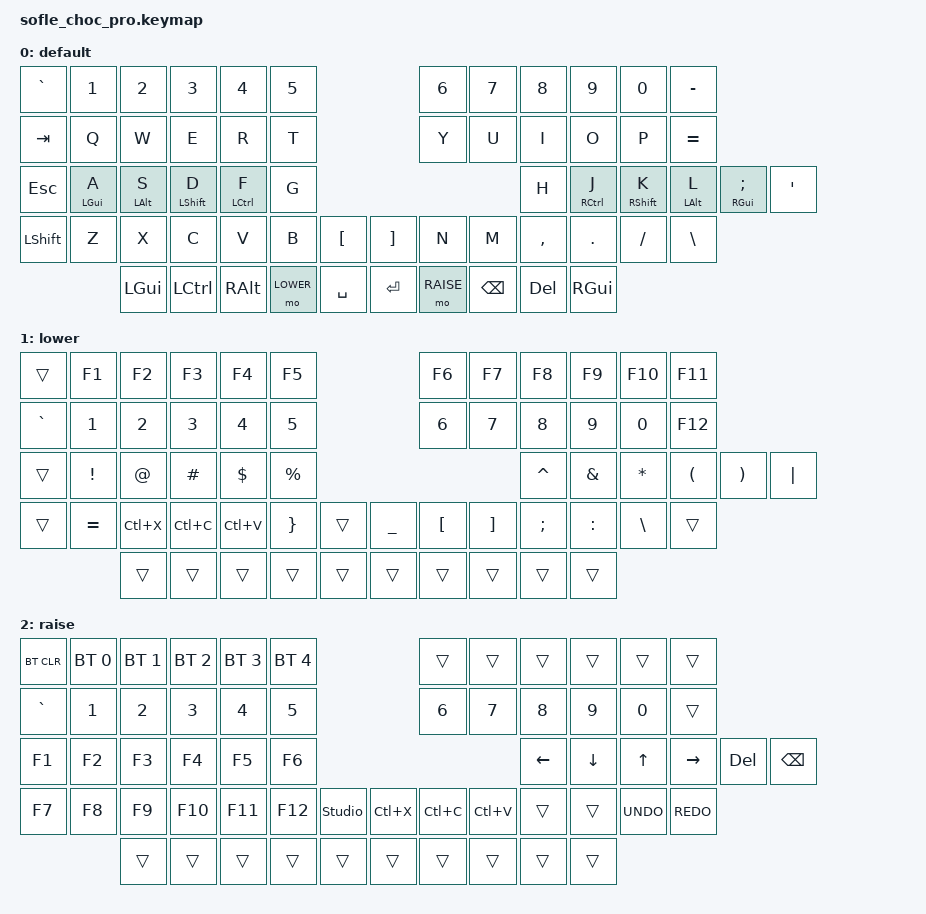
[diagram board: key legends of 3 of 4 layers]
/*
* Copyright (c) 2020 The ZMK Contributors
*
* SPDX-License-Identifier: MIT
*/

#include <behaviors.dtsi>
#include <dt-bindings/zmk/bt.h>
#include <dt-bindings/zmk/ext_power.h>
#include <dt-bindings/zmk/keys.h>
#include <dt-bindings/zmk/rgb.h>

#define BASE 0
#define LOWER 1
#define RAISE 2
#define ADJUST 3

/ {
    // Activate ADJUST layer by pressing raise and lower

    conditional_layers {
        compatible = "zmk,conditional-layers";

        adjust_layer {
            if-layers = <LOWER RAISE>;
            then-layer = <ADJUST>;
        };
    };

    behaviors {
        hml_pinky: hml_pinky {
            compatible = "zmk,behavior-hold-tap";
            label = "HML_PINKY";
            bindings = <&kp>, <&kp>;

            #binding-cells = <2>;
            tapping-term-ms = <250>;
            quick-tap-ms = <150>;
            require-prior-idle-ms = <10>;
            flavor = "balanced";
            hold-trigger-on-release;
            hold-trigger-key-positions = <28 27 26 25>;
        };

        hml_ring: hml_ring {
            compatible = "zmk,behavior-hold-tap";
            label = "HML_RING";
            bindings = <&kp>, <&kp>;

            #binding-cells = <2>;
            tapping-term-ms = <220>;
            quick-tap-ms = <150>;
            require-prior-idle-ms = <10>;
            flavor = "balanced";
            hold-trigger-on-release;
            hold-trigger-key-positions = <28 27 26 25>;
        };

        hml_middle: hml_middle {
            compatible = "zmk,behavior-hold-tap";
            label = "HML_MIDDLE";
            bindings = <&kp>, <&kp>;

            #binding-cells = <2>;
            tapping-term-ms = <190>;
            quick-tap-ms = <150>;
            require-prior-idle-ms = <10>;
            flavor = "balanced";
            hold-trigger-on-release;
            hold-trigger-key-positions = <28 27 26 25>;
        };

        hml_index: hml_index {
            compatible = "zmk,behavior-hold-tap";
            label = "HML_INDEX";
            bindings = <&kp>, <&kp>;

            #binding-cells = <2>;
            tapping-term-ms = <170>;
            quick-tap-ms = <150>;
            require-prior-idle-ms = <10>;
            flavor = "balanced";
            hold-trigger-on-release;
            hold-trigger-key-positions = <28 27 26 25>;
        };

        hmr_index: hmr_index {
            compatible = "zmk,behavior-hold-tap";
            label = "HMR_INDEX";
            bindings = <&kp>, <&kp>;

            #binding-cells = <2>;
            tapping-term-ms = <170>;
            quick-tap-ms = <150>;
            require-prior-idle-ms = <10>;
            flavor = "balanced";
            hold-trigger-on-release;
            hold-trigger-key-positions = <31 32 33 34>;
        };

        hmr_middle: hmr_middle {
            compatible = "zmk,behavior-hold-tap";
            label = "HMR_MIDDLE";
            bindings = <&kp>, <&kp>;

            #binding-cells = <2>;
            tapping-term-ms = <190>;
            quick-tap-ms = <150>;
            require-prior-idle-ms = <10>;
            flavor = "balanced";
            hold-trigger-on-release;
            hold-trigger-key-positions = <31 32 33 34>;
        };

        hmr_ring: hmr_ring {
            compatible = "zmk,behavior-hold-tap";
            label = "HMR_RING";
            bindings = <&kp>, <&kp>;

            #binding-cells = <2>;
            tapping-term-ms = <220>;
            quick-tap-ms = <150>;
            require-prior-idle-ms = <10>;
            flavor = "balanced";
            hold-trigger-on-release;
            hold-trigger-key-positions = <31 32 33 34>;
        };

        hmr_pinky: hmr_pinky {
            compatible = "zmk,behavior-hold-tap";
            label = "HMR_PINKY";
            bindings = <&kp>, <&kp>;

            #binding-cells = <2>;
            tapping-term-ms = <250>;
            quick-tap-ms = <150>;
            require-prior-idle-ms = <10>;
            flavor = "balanced";
            hold-trigger-on-release;
            hold-trigger-key-positions = <31 32 33 34>;
        };
    };

    keymap {
        compatible = "zmk,keymap";

        default_layer {
            display-name = "default";

            // ------------------------------------------------------------------------------------------------------------
            // |  `   |  1   |  2   |  3   |  4   |  5   |          |  6   |  7   |  8   |  9   |  0   |  -   |
            // | TAB  |  Q   |  W   |  E   |  R   |  T   |          |  Y   |  U   |  I   |  O   |  P   |  =   |
            // | ESC  | GUI/A| ALT/S| SHFT/D| CTRL/F|  G | |  H  | RCTRL/J| RSHFT/K| RALT/L| RGUI/;|  '   |
            // | SHFT |  Z   |  X   |  C   |  V   |  B   |  [   |  ]   |  N   |  M   |  ,   |  .   |  /   |  \\  |
            //              | GUI  | CTRL | ALT  | LOWER| SPACE | ENTER| RAISE| BSPC | DEL  | GUI  |

            bindings = <
&kp GRAVE    &kp N1            &kp N2            &kp N3             &kp N4          &kp N5                                        &kp N6     &kp N7           &kp N8           &kp N9           &kp N0                    &kp MINUS
&kp TAB      &kp Q             &kp W             &kp E              &kp R           &kp T    &kp Y                                         &kp U       &kp I             &kp O             &kp P                     &kp EQUAL
&kp ESCAPE   &hml_pinky LEFT_GUI A   &hml_ring LEFT_ALT S   &hml_middle LEFT_SHIFT D  &hml_index LCTRL F    &kp G    &kp H                                         &hmr_index RCTRL J &hmr_middle RSHFT K      &hmr_ring LEFT_ALT L    &hmr_pinky RIGHT_GUI SEMICOLON  &kp SQT
&kp LSHFT    &kp Z             &kp X             &kp C              &kp V           &kp B    &kp LEFT_BRACKET &kp RIGHT_BRACKET   &kp N       &kp M            &kp COMMA          &kp DOT                 &kp FSLH                &kp BACKSLASH
                              &kp LGUI          &kp LEFT_CONTROL   &kp RIGHT_ALT   &mo LOWER &kp SPACE        &kp ENTER           &mo RAISE   &kp BACKSPACE    &kp DELETE         &kp RGUI
            >;
        };

        lower_layer {
            display-name = "lower";

            // ------------------------------------------------------------------------------------------------------------
            // |      |  F1  |  F2  |  F3  |  F4  |  F5  |          |  F6  |  F7  |  F8  |  F9  |  F10 |  F11 |
            // |  `   |  1   |  2   |  3   |  4   |  5   |          |  6   |  7   |  8   |  9   |  0   |  F12 |
            // |      |  !   |  @   |  #   |  $   |  %   |          |  ^   |  &   |  *   |  (   |  )   |  |   |
            // |      |  =   | CUT  | COPY | PASTE|  }   |          |  _  |  [   |  ]   |  ;   |  :   |  \\  |      |
            //              |      |      |      |       |          |      |      |      |       |      |

            bindings = <
&trans       &kp F1       &kp F2       &kp F3       &kp F4       &kp F5                        &kp F6       &kp F7       &kp F8       &kp F9       &kp F10      &kp F11
&kp GRAVE    &kp N1       &kp N2       &kp N3       &kp N4       &kp N5        &kp N6                       &kp N7       &kp N8       &kp N9       &kp N0       &kp F12
&trans       &kp EXCL     &kp AT       &kp HASH     &kp DLLR     &kp PRCNT     &kp CARET                    &kp AMPS     &kp ASTRK    &kp LPAR     &kp RPAR     &kp PIPE
&trans       &kp EQUAL    &kp LC(X)   &kp LC(C)   &kp LC(V)   &kp RBRC      &trans        &kp UNDER     &kp LBKT     &kp RBKT     &kp SEMI     &kp COLON    &kp BSLH     &trans
                        &trans       &trans       &trans       &trans        &trans        &trans        &trans       &trans       &trans       &trans
            >;
        };

        raise_layer {
            display-name = "raise";

            // ------------------------------------------------------------------------------------------------------------
            // | BTCLR | BT1  | BT2  | BT3  | BT4  | BT5  |          |      |      |      |      |      |      |
            // |   `   |  1   |  2   |  3   |  4   |  5   |          |  6   |  7   |  8   |  9   |  0   |      |
            // |  F1   |  F2  |  F3  |  F4  |  F5  |  F6  |   <-     | LEFT | DOWN |  UP  | RIGHT|  DEL | BKSPC |
            // |  F7   |  F8  |  F9  |  F10 |  F11 |  F12 |  UNLOCK  | CUT  | COPY | PASTE|      |      | UNDO | REDO |
            //              |      |      |      |      |      |      |      |      |      |      |      |

            bindings = <
&bt BT_CLR     &bt BT_SEL 0    &bt BT_SEL 1    &bt BT_SEL 2    &bt BT_SEL 3    &bt BT_SEL 4                          &trans         &trans            &trans            &trans           &trans         &trans
&kp GRAVE &kp N1 &kp N2 &kp N3  &kp N4  &kp N5                       &kp N6      &kp N7    &kp N8    &kp N9   &kp N0    &trans
&kp F1    &kp F2 &kp F3 &kp F4  &kp F5  &kp F6        &kp LEFT_ARROW         &kp DOWN_ARROW  &kp UP_ARROW      &kp RIGHT         &kp DEL          &kp BSPC
&kp F7    &kp F8 &kp F9 &kp F10 &kp F11 &kp F12     &studio_unlock          &kp LC(X)        &kp LC(C)       &kp LC(V)       &trans           &trans          &kp K_UNDO       &kp K_REDO
                             &trans         &trans         &trans         &trans           &trans           &trans             &trans           &trans            &trans           &trans
            >;
        };


        adjust_layer {
            // ----------------------------------------------------------------------------------------------------------------------------
            // | BTCLR | BT1  | BT2  | BT3  | BT4  | BT5  |          | NONE | NONE | NONE | NONE | NONE | NONE |
            // | EPTOG | HUD  | HUI  | SAD  | SAI  | EFF  |          | NONE | NONE | NONE | NONE | NONE | NONE |
            // | TOGGL | BRD  | BRI  | NONE | NONE | NONE |          | NONE | NONE | NONE | NONE | NONE | NONE |
            // | NONE  | NONE | NONE | NONE | NONE | NONE | VOL- | VOL+ | NONE | NONE | NONE | NONE | NONE | NONE |
            //              | NONE | NONE | NONE | NONE | NONE | NONE | NONE | NONE | NONE | NONE |

            display-name = "adjust";
            bindings = <
&bt BT_CLR     &bt BT_SEL 0    &bt BT_SEL 1    &bt BT_SEL 2    &bt BT_SEL 3    &bt BT_SEL 4                          &none  &none  &none  &none  &none  &none
&ext_power EP_TOG &rgb_ug RGB_HUD &rgb_ug RGB_HUI &rgb_ug RGB_SAD &rgb_ug RGB_SAI &rgb_ug RGB_EFF                         &none  &none  &none  &none  &none  &none
&rgb_ug RGB_TOG   &rgb_ug RGB_BRD &rgb_ug RGB_BRI &none           &none           &none                                    &none  &none  &none  &none  &none  &none
&none          &none           &none           &none           &none           &none         &kp C_VOL_DN                      &kp C_VOL_UP  &none  &none  &none  &none  &none  &none  &none
                              &none           &none           &none           &none           &none           &none  &none  &none  &none  &none
            >;
        };
    };
};
